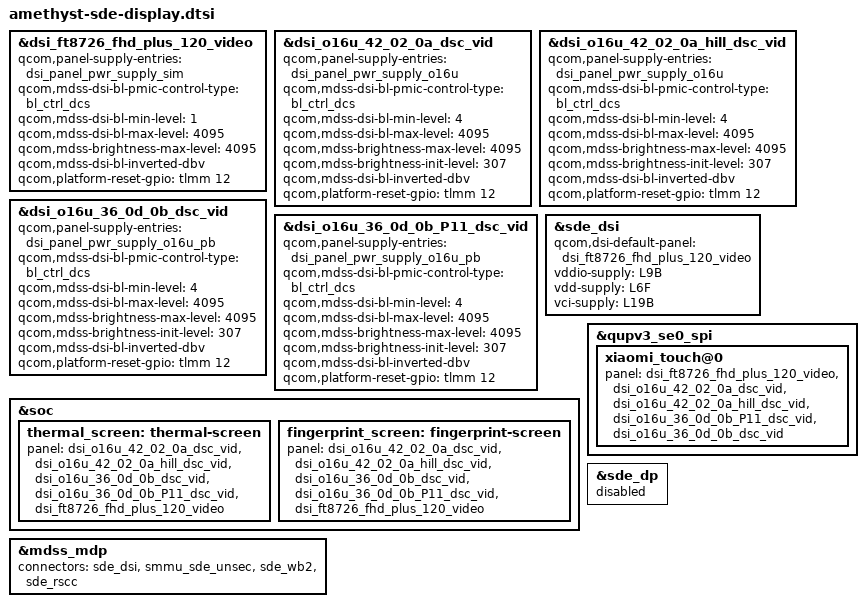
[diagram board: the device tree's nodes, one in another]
#include "volcano-sde-display.dtsi"

&dsi_ft8726_fhd_plus_120_video {
	qcom,panel-supply-entries = <&dsi_panel_pwr_supply_sim>;
	qcom,mdss-dsi-bl-pmic-control-type = "bl_ctrl_dcs";
	qcom,mdss-dsi-bl-min-level = <1>;
	qcom,mdss-dsi-bl-max-level = <4095>;
	qcom,mdss-brightness-max-level = <4095>;
	qcom,mdss-dsi-bl-inverted-dbv;
	qcom,platform-reset-gpio = <&tlmm 12 0>;
};

&dsi_o16u_42_02_0a_dsc_vid {
	qcom,panel-supply-entries = <&dsi_panel_pwr_supply_o16u>;
	qcom,mdss-dsi-bl-pmic-control-type = "bl_ctrl_dcs";
	qcom,mdss-dsi-bl-min-level = <4>;
	qcom,mdss-dsi-bl-max-level = <4095>;
	qcom,mdss-brightness-max-level = <4095>;
	qcom,mdss-brightness-init-level = <307>;
	qcom,mdss-dsi-bl-inverted-dbv;
	qcom,platform-reset-gpio = <&tlmm 12 0>;
};

&dsi_o16u_42_02_0a_hill_dsc_vid {
	qcom,panel-supply-entries = <&dsi_panel_pwr_supply_o16u>;
	qcom,mdss-dsi-bl-pmic-control-type = "bl_ctrl_dcs";
	qcom,mdss-dsi-bl-min-level = <4>;
	qcom,mdss-dsi-bl-max-level = <4095>;
	qcom,mdss-brightness-max-level = <4095>;
	qcom,mdss-brightness-init-level = <307>;
	qcom,mdss-dsi-bl-inverted-dbv;
	qcom,platform-reset-gpio = <&tlmm 12 0>;
};

&dsi_o16u_36_0d_0b_dsc_vid {
	qcom,panel-supply-entries = <&dsi_panel_pwr_supply_o16u_pb>;
	qcom,mdss-dsi-bl-pmic-control-type = "bl_ctrl_dcs";
	qcom,mdss-dsi-bl-min-level = <4>;
	qcom,mdss-dsi-bl-max-level = <4095>;
	qcom,mdss-brightness-max-level = <4095>;
	qcom,mdss-brightness-init-level = <307>;
	qcom,mdss-dsi-bl-inverted-dbv;
	qcom,platform-reset-gpio = <&tlmm 12 0>;
};

&dsi_o16u_36_0d_0b_P11_dsc_vid {
	qcom,panel-supply-entries = <&dsi_panel_pwr_supply_o16u_pb>;
	qcom,mdss-dsi-bl-pmic-control-type = "bl_ctrl_dcs";
	qcom,mdss-dsi-bl-min-level = <4>;
	qcom,mdss-dsi-bl-max-level = <4095>;
	qcom,mdss-brightness-max-level = <4095>;
	qcom,mdss-brightness-init-level = <307>;
	qcom,mdss-dsi-bl-inverted-dbv;
	qcom,platform-reset-gpio = <&tlmm 12 0>;
};

&sde_dsi {
	qcom,dsi-default-panel = <&dsi_ft8726_fhd_plus_120_video>;
	vddio-supply = <&L9B>;
	vdd-supply = <&L6F>;
	vci-supply = <&L19B>;
};

&soc {
	thermal_screen: thermal-screen {
		panel = <&dsi_o16u_42_02_0a_dsc_vid
			&dsi_o16u_42_02_0a_hill_dsc_vid
			&dsi_o16u_36_0d_0b_dsc_vid
			&dsi_o16u_36_0d_0b_P11_dsc_vid
			&dsi_ft8726_fhd_plus_120_video>;
	};
	fingerprint_screen: fingerprint-screen {
		panel = <&dsi_o16u_42_02_0a_dsc_vid
			&dsi_o16u_42_02_0a_hill_dsc_vid
			&dsi_o16u_36_0d_0b_dsc_vid
			&dsi_o16u_36_0d_0b_P11_dsc_vid
			&dsi_ft8726_fhd_plus_120_video>;
	};
};

&qupv3_se0_spi {
		xiaomi_touch@0 {
			panel = <&dsi_ft8726_fhd_plus_120_video
					&dsi_o16u_42_02_0a_dsc_vid
					&dsi_o16u_42_02_0a_hill_dsc_vid
					&dsi_o16u_36_0d_0b_P11_dsc_vid
					&dsi_o16u_36_0d_0b_dsc_vid>;
        };
};

&mdss_mdp {
	connectors = <&sde_dsi &smmu_sde_unsec &sde_wb2 &sde_rscc>;
};

&sde_dp {
	status = "disabled";
};
